# pse84 register map
Vendor: Infineon Technologies; Series: PSE84; File version: 1.0
CPU: CM33 r0p1, little endian, MPU, FPU, VTOR, 3 interrupt priority bits
Registers are 32-bit, read-write, reset 0x0 unless marked. A register's access mark holds for its fields unless they carry their own. Offsets are from the block's base; [hi:lo] are bit positions; lines under a group give offsets from that group; {n}, {i} and the like mark numbered series; 'fields as' and 'values as' point back to an identical list; <NAME> marks a mode.

## I3C (part 2 of 3) — I3C controller top
Base 0x42A50000
0x00 CORE group — registers in I3C IP core
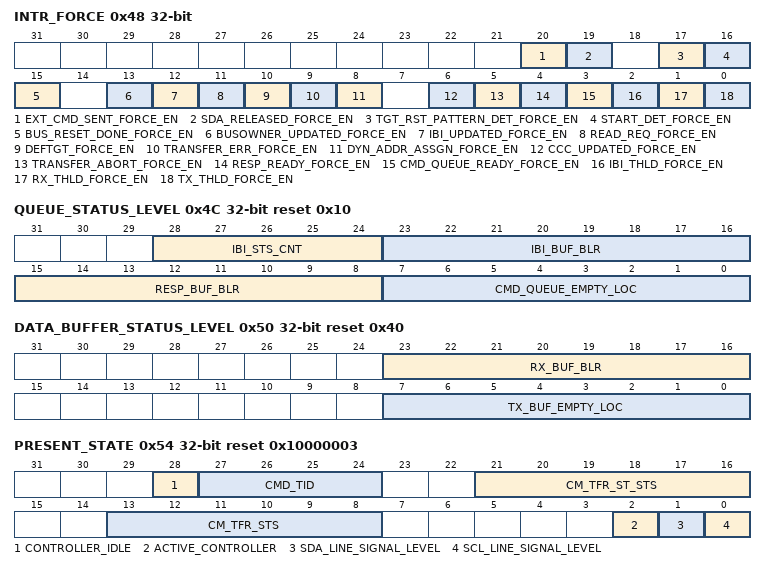
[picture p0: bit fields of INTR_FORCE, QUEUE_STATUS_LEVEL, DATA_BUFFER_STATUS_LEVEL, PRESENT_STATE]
  0x48 INTR_FORCE wo — Interrupt Force Enable Register
    [20] EXT_CMD_SENT_FORCE_EN
    [19] SDA_RELEASED_FORCE_EN — SDA Released from Stuck state Force Enable. This field is used in target mode of operation
    [17] TGT_RST_PATTERN_DET_FORCE_EN — Target Reset Pattern Detection Interrupt force Enable
    [16] START_DET_FORCE_EN — START Detection Interrupt force Enable
    [15] BUS_RESET_DONE_FORCE_EN — Bus Reset Pattern Generation Done force Enable
    [13] BUSOWNER_UPDATED_FORCE_EN — Bus owner Updated Force Enable
    [12] IBI_UPDATED_FORCE_EN — IBI Updated Force Enable This field is only valid when functioning as a Target.
    [11] READ_REQ_FORCE_EN — Read Request Received Force Enable This field is only valid when functioning as a Target.
    [10] DEFTGT_FORCE_EN — Define Target CCC Received Force Enable
    [9] TRANSFER_ERR_FORCE_EN — Transfer Error Force Enable
    [8] DYN_ADDR_ASSGN_FORCE_EN — Dynamic Address Assigned Force Enable This field is only valid when functioning as a Target.
    [6] CCC_UPDATED_FORCE_EN — CCC Table Updated Force Enable. This field is only valid when functioning as a Target.
    [5] TRANSFER_ABORT_FORCE_EN — Transfer Abort Force Enable. This field is only valid when functioning as the Active Controller.
    [4] RESP_READY_FORCE_EN — Response Queue Ready Force Enable
    [3] CMD_QUEUE_READY_FORCE_EN — Command Queue Ready Force Enable
    [2] IBI_THLD_FORCE_EN — IBI Buffer Threshold Force Enable This field is only valid when functioning aa the Active Controller.
    [1] RX_THLD_FORCE_EN — Receive Buffer Threshold Force Enable
    [0] TX_THLD_FORCE_EN — Transmit Buffer Threshold Force Enable
  0x4C QUEUE_STATUS_LEVEL ro reset 0x10
    [28:24] IBI_STS_CNT — <HIDDEN>
    [23:16] IBI_BUF_BLR — IBI Buffer Level Value. This field is used when functioning as the Active Controller. Contains the number of Valid IBI Status entries in the IBI Buffer.
    [15:8] RESP_BUF_BLR — Response Buffer Level Value. Contains the number of valid data entries in the response Buffer.
    [7:0] CMD_QUEUE_EMPTY_LOC — Command Queue Empty Locations. Contains the number of empty locations in the command Buffer.
  0x50 DATA_BUFFER_STATUS_LEVEL ro reset 0x40
    [23:16] RX_BUF_BLR — Receive Buffer Level Value. Contains the number of valid data entries in the receive Buffer.
    [7:0] TX_BUF_EMPTY_LOC — Transmit Buffer Empty Level Value. Contains the number of empty locations in the transmit Buffer.
  0x54 PRESENT_STATE ro reset 0x10000003
    [28] CONTROLLER_IDLE — This bit is only valid when this I3C Device is functioning the Active Controller, and reflects whether the block is in the Idle state or not. This bit is set when all the Queues (Command , Response, IBI) and Buffers (Transmit and Receive) are empty and the Controller State machine is in Idle state. Values: 0x0 Controller is not in IDLE State 0x1 Controller is in IDLE State.
    [27:24] CMD_TID — This field reflects the Transaction-ID of the current executing command.
    [21:16] CM_TFR_ST_STS — Active Controller Transfer State Status. This bit is only valid when this I3C Device is functioning the Active Controller, and indicates the state of current transfer currently executing by the I3C block. Values: 0x0: IDLE (Controller is Idle state, waiting for commands from application or Target initated In-band Interrupt) 0x1: START Generation State. 0x2: RESTART Generation State. 0x3: STOP Generation State. 0x4: START Hold Generation for the Target Initiated START State. 0x5: Broadcast Write Address Header(7'h7E,W) Generation State. 0x6: Broadcast Read Address Header(7'h7E,R) Generation State. 0x7: Dynamic Address Assignment State. 0x8: Target Address Generation State. 0xB: CCC Byte Generation State. 0xC: HDR Command Generation State. 0xD: Write Data Transfer State. 0xE: Read Data Transfer State. 0xF: In-Band Interrupt (TIR) Read Data State. 0x10: In-Band Interrupt Auto-Disable State 0x11: HDR-DDR CRC Data Generation/Receive State. 0x12: Clock Extension State. 0x13: Halt State.
    [13:8] CM_TFR_STS — Transfer Type Status. Indicates the type of transfer currently executing by the I3C block. When functioning as the Active Controller, possible values are: 0x0: IDLE (Block is in Idle state, waiting for commands from application or Target initated In-band Interrupt) 0x1: Broadcast CCC Write Transfer. 0x2: Directed CCC Write Transfer. 0x3: Directed CCC Read Transfer. 0x4: ENTDAA Address Assignment Transfer. 0x5: SETDASA Address Assignment Transfer. 0x6: Private I3C SDR Write Transfer. 0x7: Private I3C SDR Read Transfer. 0x8: Private I2C SDR Write Transfer. 0x9: Private I2C SDR Read Transfer. 0xA: Private HDR Ternary Symbol (TS) Write Transfer. 0xB: Private HDR Ternary Symbol (TS) Read Transfer. 0xC: Private HDR Double-Data Rate (DDR) Write Transfer. 0xD: Private HDR Double-Data Rate (DDR) Read Transfer. 0xE: Servicing In-Band Interrupt Transfer. 0xF: Halt state (Block is in Halt State, waiting for the application to resume through DEVICE_CTRL Register) When functioning as a Target, possible values are: 0x0: IDLE (Block is in Idle state) 0x1: Hot-Join transfer state 0x2: IBI transfer state 0x3: Controller write transfer ongoing 0x4: Read data prefetch state 0x5: Controller read transfer ongoing 0x6: Bock is controller in Halt State waiting for resume from application
    [2] ACTIVE_CONTROLLER — This Bit is used to check whether the block is currently the Active Controller or not. The Active Controller is the Controller that owns the SCL line. Values: 0x0: Secondary Controller is not the Active Controller and needs to request to be the Active Controller before initiating any transfer on the line. 0x1: Secondary Controller is the Active Controller and can initiate transfers on the line.
    [1] SDA_LINE_SIGNAL_LEVEL — This bit is only valid when this I3C Device is functioning the Active Controller, and is used for debug and error recovery. This bit reflects the value of the SDA line as observed inside the block (after input synchronization).
    [0] SCL_LINE_SIGNAL_LEVEL — This bit is only valid when this I3C Device is functioning the Active Controller, and is used for debug and error recovery. This bit reflects the value of the SCL line as observed inside the block (after input synchronization).
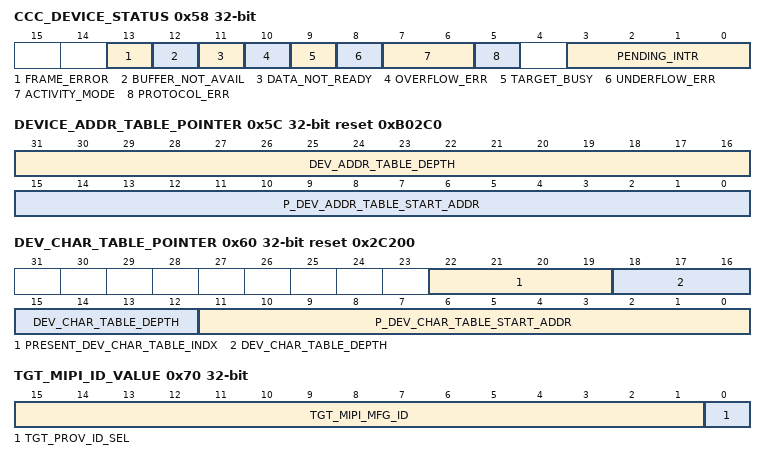
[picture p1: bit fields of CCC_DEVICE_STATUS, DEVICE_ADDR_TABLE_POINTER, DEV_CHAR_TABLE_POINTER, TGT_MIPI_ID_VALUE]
  0x58 CCC_DEVICE_STATUS ro — Device Operating Status Register.
    [13] FRAME_ERROR — Frame Error This bit is only valid when this I3C Device is functioning as a Target, and is set when a private write request initiated by the Active Controller has a frame error in HDR-DDR/HDR-TSP/TSL mode. This is cleared only after the Active Controller reads the device status through GETSTATUS_CCC.
    [12] BUFFER_NOT_AVAIL — Buffer not available This bit is only valid when this I3C Device is functioning as a Target, and is set when a private write request initiated by the Active Controller is NACKED because of RX buffer not having RX_BUF_THLD number of empty locations or Response buffer being full. In SDR mode of operation this is cleared when the Active Controller issues GETSTATUS CCC or upon space becoming available in the buffer and the successful completion of the next write transfer. In HDR mode of operation it is cleared only when the Active Controller issues GETSTATUS CCC.
    [11] DATA_NOT_READY — Data not ready This bit is only valid when this I3C Device is functioning as a Target, and is set when private a private read request initiated by the Active Controller is NACKED because of any of the following conditions Command FIFO Empty. Transmit FIFO threshold is not met. Response FIFO Full. This bit is cleared when the Active Controller issues GETSTATUS CCC or upon successful completion of the subsequent read transfer.
    [10] OVERFLOW_ERR — Overflow Error This bit is only valid when this I3C Device is functioning as a Target, and is set when an overflow error condition is detected during a private write transfer initiated by the Active Controller. This is cleared only after the Active Controller reads the Device Status through GETSTATUS CCC.
    [9] TARGET_BUSY — Target Busy This bit is set if any change is made by the Active Controller to the MRL register or occurance of any error. It is cleared after Target application resumes the block operation by writing to the RESUME bit of the DEVICE_CONTROL register.
    [8] UNDERFLOW_ERR — Underflow error This bit is only valid when this I3C Device is functioning as a Target, and is set when terminates a private read transfer initiated by the Active Controller is terminated by the device because of unavailability of data in the transmit buffer. This bit is cleared only after the Active Controller reads the Device Status through a GETSTATUS CCC.
    [7:6] ACTIVITY_MODE — Pending Interrupt This field reflects the value from I3C.CCC_GETSTATUS.ACT_MODE.
    [5] PROTOCOL_ERR — Protocol Error This bit is only valid when this I3C Device is functioning as a Target, and is set when a Parity/CRC error is encountered during a private write transfer initiated by the Active Controller.
    [3:0] PENDING_INTR — Pending Interrupt This field reflects the value from I3C.CCC_GETSTATUS.PENDING_INT.
  0x5C DEVICE_ADDR_TABLE_POINTER ro reset 0xB02C0 — Pointer for Device Address Table
    [31:16] DEV_ADDR_TABLE_DEPTH — Depth of the Device Address Table in the internal memory.
    [15:0] P_DEV_ADDR_TABLE_START_ADDR — Start Address of the Device Address Table in the internal memory.
  0x60 DEV_CHAR_TABLE_POINTER reset 0x2C200 — Pointer for Device Characteristics Table
    [22:19] PRESENT_DEV_CHAR_TABLE_INDX — Current index of the Device Characteristics Table. This field returns the current location of Device Characteristics Table index. Initially, this index points to 0. Once the complete characteristics information of a Target device is written into Device Characteristics Table during ENTDAA, this index increments by 1. The first winning device information is stored in Device Characteristics Table index 0, the second winning device information in index 1, and so on. If required, this index can be used to override the location, where characteristic information of Target devices on the I3C bus are written during ENTDAA. Hence, this field is useful only when the device is functioning as the Active Controller. During DEFTGTS CCC, the index always starts from 0. When the device is functioning as a Target, this field is read-only.
    [18:12] DEV_CHAR_TABLE_DEPTH ro — Depth of Device Characteristics Table in the internal memory.
    [11:0] P_DEV_CHAR_TABLE_START_ADDR ro — Start Address of the Device Characteristics Table in the internal memory.
  0x6C VENDOR_SPECIFIC_REG_POINTER ro reset 0xB0 — Pointer for Vendor Specific Registers.
    [15:0] P_VENDOR_REG_START_ADDR — Start Address of Vendor specific registers.
  0x70 TGT_MIPI_ID_VALUE — I3C MIPI Manufacturer ID Register
    [15:1] TGT_MIPI_MFG_ID — Specifies the MIPI Manufacturer ID (Provisioned ID [47:33]).
    [0] TGT_PROV_ID_SEL — Specifies the Provisioned ID Type Selector (Provisioned ID [32]). Values: 0x0: Vendor Fixed Value 0x1: Random Value
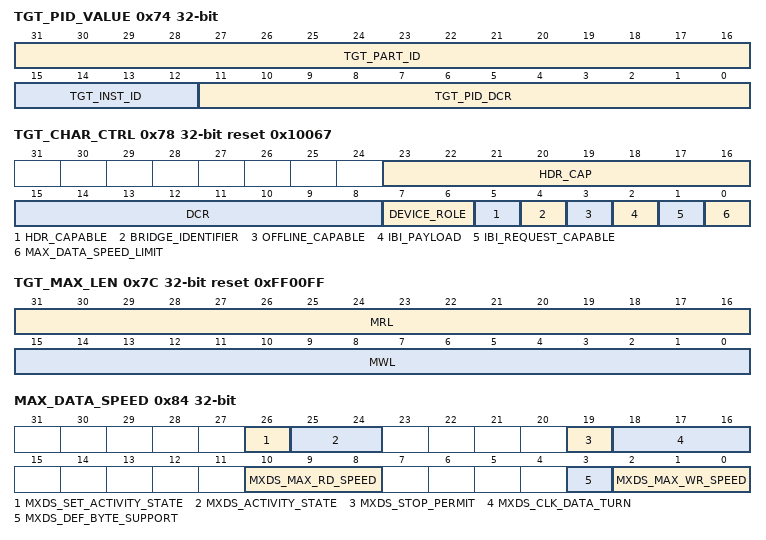
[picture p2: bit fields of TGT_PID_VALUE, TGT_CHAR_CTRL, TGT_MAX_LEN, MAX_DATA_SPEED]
  0x74 TGT_PID_VALUE — I3C Normal Provisional ID Register
    [31:16] TGT_PART_ID — Specifies the Part ID of this I3C block (PID[31:16]).
    [15:12] TGT_INST_ID — Specifies the MIPI Instance ID of this I3C block (Provisioned ID [15:12]).
    [11:0] TGT_PID_DCR — Specifies the last 12 bit of the MIPI Provisioned ID of this I3C block (Provisioned ID [11:0]).
  0x78 TGT_CHAR_CTRL reset 0x10067 — I3C Target Characteristic Register.
    [23:16] HDR_CAP ro — <HIDDEN>
    [15:8] DCR — I3C Device Characteristic Regster (DCR) Value
    [7:6] DEVICE_ROLE — Device Role field in Bus Characteristic Register (BCR[7:6]). This bit is set by default as 0x1 (device has Controller capabilities) and the application is not expected to change it. However, if the application chooses to operate the device as a Target-only device (no controlelr capability), then the Device Role can be overwritten as Target-only. Values: 0x0: I3C Target 0x1: I3C Controller capable The field is Reset to its default value upon HW/SW Reset. SW must program the values again after issuing reset.
    [5] HDR_CAPABLE — SDR Only or SDR and HDR Capable field in Bus Characteristic Register (BCR[5]). This bit can be modified by the application if it does not want to advertize the Target's HDR capability to the Active Controller. The field is Reset to its default value upon HW/SW Reset. SW must program the values again after issuing reset.
    [4] BRIDGE_IDENTIFIER ro — <HIDDEN>
    [3] OFFLINE_CAPABLE ro — <HIDDEN>
    [2] IBI_PAYLOAD ro — <HIDDEN>
    [1] IBI_REQUEST_CAPABLE ro — <HIDDEN>
    [0] MAX_DATA_SPEED_LIMIT — Max Data Speed Limitation field in Bus Characteristic Register (BCR[0]). Specifies whether or not this I3C device has a maximum data speed limitation. If this bit is set to 0, controller NACK's the GETMXDS CCC sent by the Active Controller. If this bit is set to 1, controller returns the data in MAX_DATA_SPEED and MAX_READ_TURNAROUND register in response the GETMXDS CCC sent by the Active Controller. The field is reset to its default value upon HW/SW Reset. SW must program the values again after issuing reset.
  0x7C TGT_MAX_LEN ro reset 0xFF00FF — I3C Max Write/Read Length Register.
    [31:16] MRL — I3C Device Max Read Length
    [15:0] MWL — I3C Device Max Write Length
  0x80 MAX_READ_TURNAROUND ro — MXDS Maximum Read Turnaround Time.
    [23:0] MXDS_MAX_RD_TURN — Specifies the maximum read turnaround time (in microseconds (us)) of this I3C device.
  0x84 MAX_DATA_SPEED — Maximum Data Speed Register
    [26] MXDS_SET_ACTIVITY_STATE — This bit indicates whether the Active Controller should set the Bus to the Activity State indicated in bits 25:24 before handing the Controller Role off to this I3C Device as part of the normal flow. Values: - 0x0 (SET_ACIVITY_STATE_0): The controller will not set the Bus to any Activity state. - 0x1 (SET_ACIVITY_STATE_1): The controller will set the Bus to any Activity state based on the value in 25:24 field of register
    [25:24] MXDS_ACTIVITY_STATE — This 2-bit integer indicates whether this I3C Device initially acts with a given Activity State, after becoming Active Controller on the Bus according to the Controller handoff flow Values: - 0x0 (ACIVITY_STATE_0): Acts as Activity state 0. - 0x1 (ACIVITY_STATE_1): Acts as Activity state 1. - 0x2 (ACIVITY_STATE_2): Acts as Activity state 2. - 0x3 (ACIVITY_STATE_3): Acts as Activity state 3
    [19] MXDS_STOP_PERMIT — Specifies the stop support between write and read Values: - 0x0 (STOP_PERMIT_0): Stop after write will cancel the read. - 0x1 (STOP_PERMIT_1): Target permits the write and read to be seperated by a STOP
    [18:16] MXDS_CLK_DATA_TURN
    [10:8] MXDS_MAX_RD_SPEED
    [3] MXDS_DEF_BYTE_SUPPORT — Specifies the defining byte support of GETMXDS CCC Values: - 0x0 (DEF_BYTE_0): Defining byte is not supported for GETMXDS CCC. - 0x1 (DEF_BYTE_1): Defining byte is supported for GETMXDS CCC
    [2:0] MXDS_MAX_WR_SPEED
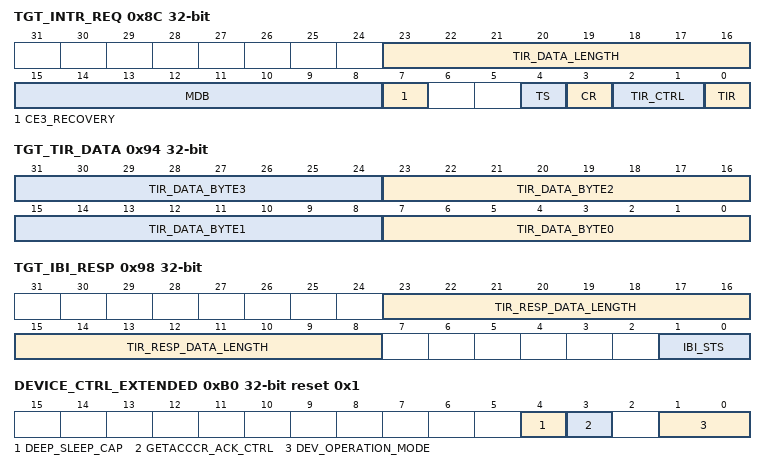
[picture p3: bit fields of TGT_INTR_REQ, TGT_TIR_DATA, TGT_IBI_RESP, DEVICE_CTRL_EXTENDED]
  0x8C TGT_INTR_REQ — Target Interrupt Request Register
    [23:16] TIR_DATA_LENGTH
    [15:8] MDB
    [7] CE3_RECOVERY
    [4] TS
    [3] CR — Controller Role Request When set, the block attempts to issue the request to become the Active Controller on the I3C bus. Once that is issued and the Active Controller accepts (ACK), or if the block is unable to issue the request, then the block clears this bit automatically and updates the IBI_STS field. If NACK response is received for the request, the block reattempts the CR upon detecting the next START condition from the Active Controller or after the Bus Available time. Once set, the application cannot clear this bit.
    [2:1] TIR_CTRL
    [0] TIR — Target Interrupt Request When set, the Target Controller attempts to issue the TIR on the I3C bus. Once issued and when the Active Controller accepts (ACK), or if the block is unable to issue the TIR, then the block clears this bit automatically and updates the IBI_STS field. If the NACK response is received for the TIR, the block reattempts the TIR upon detecting the next START condition from the Active Controller or after the Bus Available Time. Once set, the application cannot clear this bit.
  0x94 TGT_TIR_DATA — Target Interrupt Request Data Register
    [8n+7:8n] TIR_DATA_BYTE{n} (n=0..3)
  0x98 TGT_IBI_RESP ro — Target IBI Response Register
    [23:8] TIR_RESP_DATA_LENGTH, [1:0] IBI_STS
  0xB0 DEVICE_CTRL_EXTENDED reset 0x1 — Device Control Extended Register
    [4] DEEP_SLEEP_CAP
    [3] GETACCCR_ACK_CTRL — In Target mode of operation, this bit serves as a control to ACK/NACK the GETACCCR CCC from the Active Controller. Values: 0x0: ACK GETACCCR CCC 0x1: NACK GETACCCR CCC
    [1:0] DEV_OPERATION_MODE — This bit is used to select the initial device role before the block is enabled. This field should only be written before the I3C block is enabled This field is automatically updated by the block once the a role change takes place. Values: 0x0: Primary Controller (starts as the Active Controller and initializes/configures the I3C bus) 0x1: Secondary Controller (starts as a Target, but can become the Active Controller)
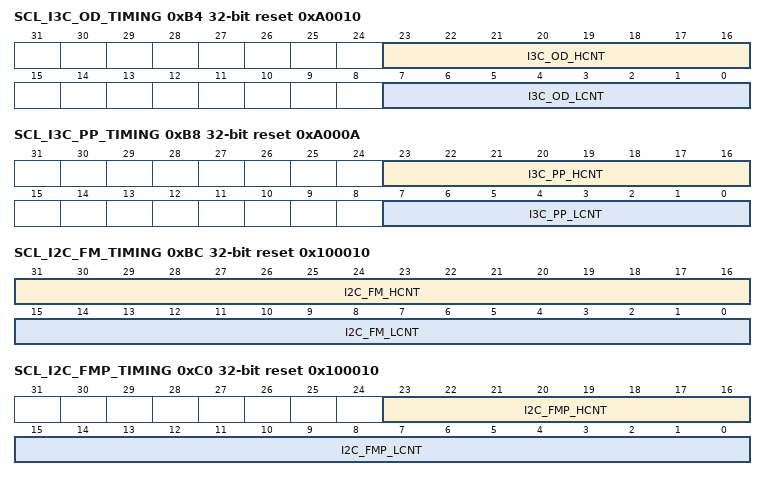
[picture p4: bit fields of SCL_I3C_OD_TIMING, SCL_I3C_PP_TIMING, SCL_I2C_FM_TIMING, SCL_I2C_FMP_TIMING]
  0xB4 SCL_I3C_OD_TIMING reset 0xA0010 — SCL I3C Open Drain Timing Register
    [23:16] I3C_OD_HCNT — I3C Open Drain High Count. SCL open-drain High count (I3C) for I3C transfers targeted to I3C devices.
    [7:0] I3C_OD_LCNT — I3C Open Drain Low Count. SCL Open-drain low count for I3C transfers targeted to I3C devices.
  0xB8 SCL_I3C_PP_TIMING reset 0xA000A — SCL I3C Push Pull Timing Register
    [23:16] I3C_PP_HCNT — I3C Push Pull High Count. SCL push-pull High count for I3C transfers targeted to I3C devices.
    [7:0] I3C_PP_LCNT — I3C Push Pull Low Count. SCL Push-pull low count for I3C transfers targeted to I3C devices.
  0xBC SCL_I2C_FM_TIMING reset 0x100010 — SCL I2C Fast Mode Timing Register
    [31:16] I2C_FM_HCNT — I2C Fast Mode High Count The SCL open-drain high count timing for I2C fast mode transfers.
    [15:0] I2C_FM_LCNT — I2C Fast Mode Low Count The SCL open-drain low count timing for I2C fast mode transfers.
  0xC0 SCL_I2C_FMP_TIMING reset 0x100010 — SCL I2C Fast Mode Plus Timing Register
    [23:16] I2C_FMP_HCNT — I2C Fast Mode Plus High Count The SCL open-drain high count timing for I2C fast mode plus transfers.
    [15:0] I2C_FMP_LCNT — I2C Fast Mode Plus Low Count The SCL open-drain low count timing for I2C fast mode plus transfers.
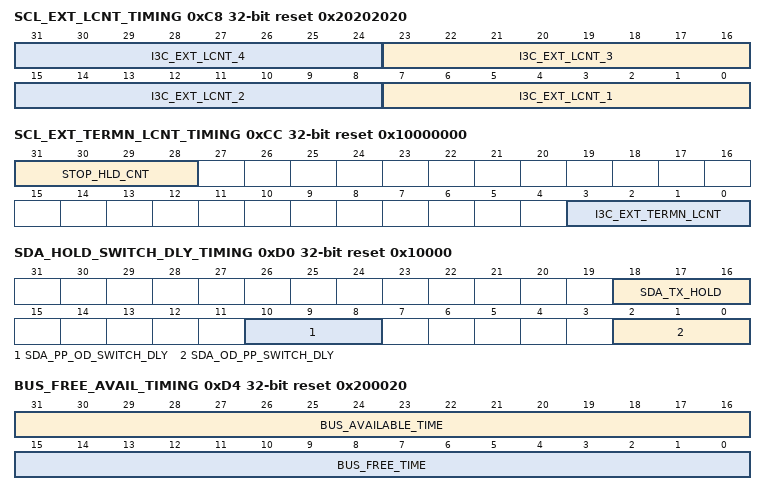
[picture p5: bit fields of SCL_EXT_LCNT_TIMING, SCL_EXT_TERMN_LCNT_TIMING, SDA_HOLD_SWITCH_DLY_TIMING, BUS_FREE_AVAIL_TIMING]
  0xC8 SCL_EXT_LCNT_TIMING reset 0x20202020 — SCL Extended Low Count Timing Register.
    [8n-1:8n-8] I3C_EXT_LCNT_{n} (n=1..4) — I3C Extended Low Count Register {n} SDR{n} uses this register field for determining the extended SCL low phase.
  0xCC SCL_EXT_TERMN_LCNT_TIMING reset 0x10000000 — SCL Termination Bit Low Count Timing Register
    [31:28] STOP_HLD_CNT
    [3:0] I3C_EXT_TERMN_LCNT — I3C Read Termination Bit Low count. Extended I3C Read Termination Bit low count for I3C Read transfers. Effective Termination-Bit Low Period is derived based on the SDR speed as shown below. SDR0 speed: I3C_PP_LCNT + I3C_EXT_TERMN_LCNT SDR1 speed: I3C_EXT_LCNT_1 + I3C_EXT_TERMN_LCNT SDR2 speed: I3C_EXT_LCNT_2 + I3C_EXT_TERMN_LCNT SDR3 speed: I3C_EXT_LCNT_3 + I3C_EXT_TERMN_LCNT SDR4 speed: I3C_EXT_LCNT_4 + I3C_EXT_TERMN_LCNT
  0xD0 SDA_HOLD_SWITCH_DLY_TIMING reset 0x10000 — SDA Hold and Mode Switch Delay Timing Register
    [18:16] SDA_TX_HOLD, [10:8] SDA_PP_OD_SWITCH_DLY, [2:0] SDA_OD_PP_SWITCH_DLY
  0xD4 BUS_FREE_AVAIL_TIMING reset 0x200020 — Bus Free and Available Timing Register
    [31:16] BUS_AVAILABLE_TIME — Bus Available Count Value This register field is used only When functioning as a Target. This field is used by the block to initiate an IBI after the STOP condition.
    [15:0] BUS_FREE_TIME — I3C Bus Free Count Value This register field is used only when functioning as the Active Controller. In a Pure Bus System, this field represents the tCAS parameter. In a Mixed Bus system, this field is expected to be programmed to tLOW of I2C Timing.
  0xD8 BUS_IDLE_TIMING reset 0x20
    [19:0] BUS_IDLE_TIME — Bus Idle Count Value This field is used by the block to initiate a Hot-Join request if the dynamic address is not valid.
  0xDC SCL_LOW_CTR_EXT_TIMEOUT reset 0x3567E0 — SCL LOW Controller Timeout
    [25:0] SCL_LOW_CTR_TIMEOUT_COUNT
  0xEC RELEASE_SDA_TIMING reset 0x4E20 — Release SDA count value.
    [19:0] RELEASE_SDA_TIME
  {0x130+4j} EXT_TX_DATA_PORT_{j} wo (j=0..3) — DWC_mipi_i3c Directed read Vendor-specific CCC {j} TX Data Port Register
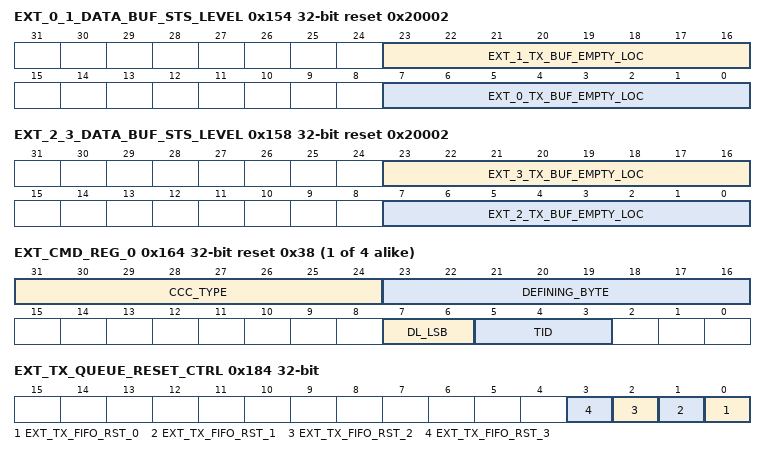
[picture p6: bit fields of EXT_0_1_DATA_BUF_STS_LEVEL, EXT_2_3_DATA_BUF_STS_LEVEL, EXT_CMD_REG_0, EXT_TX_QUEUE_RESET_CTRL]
  0x154 EXT_0_1_DATA_BUF_STS_LEVEL ro reset 0x20002 — Vendor-specific CCC types 0 and 1 Data Buffer Status Level Register
    [23:16] EXT_1_TX_BUF_EMPTY_LOC, [7:0] EXT_0_TX_BUF_EMPTY_LOC
  0x158 EXT_2_3_DATA_BUF_STS_LEVEL ro reset 0x20002 — Vendor-specific CCC types 2 and 3 Data Buffer Status Level Register
    [23:16] EXT_3_TX_BUF_EMPTY_LOC, [7:0] EXT_2_TX_BUF_EMPTY_LOC
  {0x164+4j} EXT_CMD_REG_{j} reset 0x38 (j=0..3) — TID, CCC type value and Defining Byte of Vendor-specific CCC {j} Register
    [31:24] CCC_TYPE, [23:16] DEFINING_BYTE, [7:6] DL_LSB, [5:3] TID
  0x184 EXT_TX_QUEUE_RESET_CTRL — Individual Vendor CCC buffer reset.
    [n] EXT_TX_FIFO_RST_{n} (n=0..3)
  0x200 DEV_CHAR_TABLE1_LOC1 ro reset not defined — Device Characteristic Table Location-1 of Device1, MSB_PROVISIONAL_ID
    [31:0] MSB_PROVISIONAL_ID — The 32 Most Significant Bits (MSBs) from the 48-bit MIPI Provisioned ID
  0x204 DEV_CHAR_TABLE1_LOC2 ro reset not defined — Device Characteristic Table Location-2 of Device1, LSB_PROVISIONAL_ID
    [15:0] LSB_PROVISIONAL_ID — The 16 Least Significant Bits (LSBs) from the 48-bit MIPI Provisioned ID
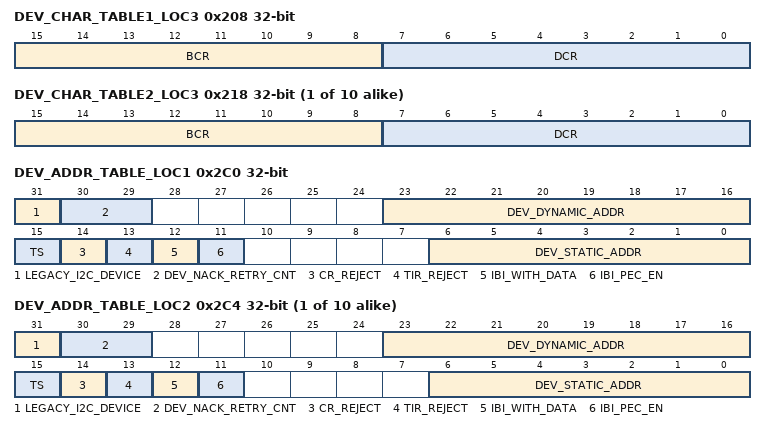
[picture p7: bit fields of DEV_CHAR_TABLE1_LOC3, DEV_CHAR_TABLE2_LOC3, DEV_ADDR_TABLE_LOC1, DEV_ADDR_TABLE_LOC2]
  0x208 DEV_CHAR_TABLE1_LOC3 ro reset not defined — Device Characteristic Table Location-3 of Device1, BCR, DCR
    [15:8] BCR — Bus Characteristic Register (BCR)
    [7:0] DCR — Device Characteristic Register (DCR)
  0x20C DEV_CHAR_TABLE1_LOC4 ro reset not defined — Device Characteristic Table Location-4 of Device1, DEV_DYNAMIC_ADDR
    [7:0] DEV_DYNAMIC_ADDR — Dynamic Address assigned to the device.
  {0x1F0+0x10*j} DEV_CHAR_TABLE{j}_LOC1 ro reset not defined (j=2..6) — Device Characteristic Table Location-1 of Device{j}
    fields as CORE.DEV_CHAR_TABLE1_LOC1
  {0x1F4+0x10*j} DEV_CHAR_TABLE{j}_LOC2 ro reset not defined (j=2..4) — Device Characteristic Table Location-2 of Device{j}
    fields as CORE.DEV_CHAR_TABLE1_LOC2
  {0x1F8+0x10*j} DEV_CHAR_TABLE{j}_LOC3 ro reset not defined (j=2..11) — Device Characteristic Table Location-3 of Device{j}
    fields as CORE.DEV_CHAR_TABLE1_LOC3
  {0x1FC+0x10*j} DEV_CHAR_TABLE{j}_LOC4 ro reset not defined (j=2..7) — Device Characteristic Table Location-4 of Device{j}
    [7:0] DEV_DYNAMIC_ADDR — Dynamic Address assigned to the device.
  0x244 DEV_CHAR_TABLE5_LOC2 ro reset not defined — Device Characteristic Table Location-4 of Device10
    fields as CORE.DEV_CHAR_TABLE1_LOC2
  {0x1F4+0x10*j} DEV_CHAR_TABLE{j}_LOC2 ro reset not defined (j=6..10) — Device Characteristic Table Location-2 of Device{j}
    fields as CORE.DEV_CHAR_TABLE1_LOC2
  0x260 DEV_CHAR_TABLE7_LOC1 ro reset not defined — Device Address Table of Device3
    fields as CORE.DEV_CHAR_TABLE1_LOC1
  {0x1F0+0x10*j} DEV_CHAR_TABLE{j}_LOC1 ro reset not defined (j=8..11) — Device Characteristic Table Location-1 of Device{j}
    fields as CORE.DEV_CHAR_TABLE1_LOC1
  0x27C DEV_CHAR_TABLE8_LOC4 ro reset not defined — Device Address Table of Device10
    [7:0] DEV_DYNAMIC_ADDR — Dynamic Address assigned to the device.
  {0x1FC+0x10*j} DEV_CHAR_TABLE{j}_LOC4 ro reset not defined (j=9..11) — Device Characteristic Table Location-4 of Device{j}
    [7:0] DEV_DYNAMIC_ADDR — Dynamic Address assigned to the device.
  0x2A4 DEV_CHAR_TABLE11_LOC2 ro reset not defined — 0
    fields as CORE.DEV_CHAR_TABLE1_LOC2
  0x2C0 DEV_ADDR_TABLE_LOC1 reset not defined — Device Address Table of Device1
    [31] LEGACY_I2C_DEVICE — Legacy I2C Device Values: 0x0: Device is an I3C Device 0x1: Device is a Legacy I2C Device
    [30:29] DEV_NACK_RETRY_CNT — This field is used to set the Device NACK Retry count for the particular device. If the Device NACKs for the device address, the block automatically retries the transfer until this count expires. If the Target NACKs for the mentioned number of retries, then the block generates an error response and moves to the Halt state. This feature is used for Retry Model for the following features mentioned in the I3C Specification: => Retry Model for Direct GET CCC Commands => The incoming TIR-IBI matches with the Target address initated by the Active Controller
    [23:16] DEV_DYNAMIC_ADDR — Device Dynamic Address with parity. This field consists of a Dynamic Address and a Parity Bit. The LSBs [22:16] consist of the Dynamic Address to be assigned for the winning I3C device when using ENTDAA command. The MSB [23] is the odd parity of the 7-bit Dynamic Address used for ENTDAA address assignment (~XOR(DEV_DYNAMIC_ADDR[22:16])
    [15] TS
    [14] CR_REJECT
    [13] TIR_REJECT
    [12] IBI_WITH_DATA
    [11] IBI_PEC_EN
    [6:0] DEV_STATIC_ADDR — Device Static Address.
  {0x2BC+4j} DEV_ADDR_TABLE_LOC{j} reset not defined (j=2..11) — Device Address Table of Device{j}
    [31] LEGACY_I2C_DEVICE — Legacy I2C Device Values: 0x0: Device is a Legacy I2C Device 0x1: Device is an I3C Device
    [30:29] DEV_NACK_RETRY_CNT — This field is used to set the Device NACK Retry count for the particular device. If the Device NACKs for the device address, the block automatically retries the transfer until this count expires. If the Target NACKs for the mentioned number of retries, then the block generates an error response and moves to the Halt state. This feature is used for Retry Model for the following features mentioned in the I3C Specification: => Retry Model for Direct GET CCC Commands => The incoming TIR-IBI matches with the Target address initated by the Active Controller
    [23:16] DEV_DYNAMIC_ADDR — Device Dynamic Address with parity. This field consists of a Dynamic Address and a Parity Bit. The LSBs [22:16] consist of the Dynamic Address to be assigned for the winning I3C device when using ENTDAA command. The MSB [23] is the odd parity of the 7-bit Dynamic Address used for ENTDAA address assignment (~XOR(DEV_DYNAMIC_ADDR[22:16])
    [15] TS
    [14] CR_REJECT
    [13] TIR_REJECT
    [12] IBI_WITH_DATA
    [11] IBI_PEC_EN
    [6:0] DEV_STATIC_ADDR — Device Static Address.
